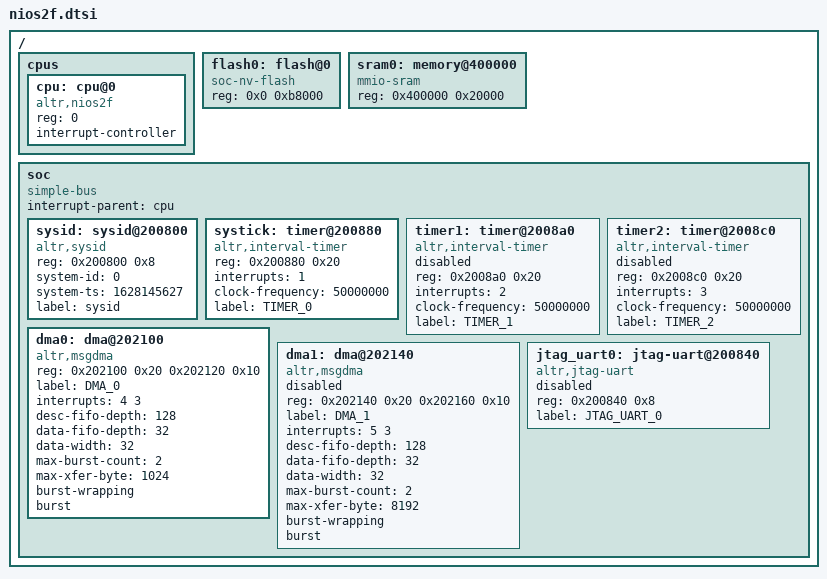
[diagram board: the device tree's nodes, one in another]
/*
 * Copyright (c) 2021 TiaC Systems
 * Copyright (c) 2018 Intel Corporation
 * SPDX-License-Identifier: Apache-2.0
 */

#include "skeleton.dtsi"

/ {
	cpus {
		#address-cells = <1>;
		#size-cells = <0>;

		cpu: cpu@0 {
			device_type = "cpu";
			compatible = "altr,nios2f";
			reg = <0>;
			interrupt-controller;
			#interrupt-cells = <1>;
		};
	};

	flash0: flash@0 {
		compatible = "soc-nv-flash";
		reg = <0x0 0xb8000>;
	};

	sram0: memory@400000 {
		compatible = "mmio-sram";
		reg = <0x400000 0x20000>;
	};

	soc {
		#address-cells = <1>;
		#size-cells = <1>;
		compatible = "simple-bus";
		interrupt-parent = <&cpu>;
		ranges;

		sysid: sysid@200800 {
			compatible = "altr,sysid";
			reg = <0x200800 0x8>;
			system-id = <0>;
			system-ts = <1628145627>;
			label = "sysid";
		};

		systick: timer@200880 {
			compatible = "altr,interval-timer";
			reg = <0x200880 0x20>;
			interrupts = <1>;
			clock-frequency = <50000000>;
			label = "TIMER_0";
		};

		timer1: timer@2008a0 {
			compatible = "altr,interval-timer";
			reg = <0x2008a0 0x20>;
			interrupts = <2>;
			clock-frequency = <50000000>;
			label = "TIMER_1";

			status = "disabled";
		};

		timer2: timer@2008c0 {
			compatible = "altr,interval-timer";
			reg = <0x2008c0 0x20>;
			interrupts = <3>;
			clock-frequency = <50000000>;
			label = "TIMER_2";

			status = "disabled";
		};

		dma0: dma@202100 {
			compatible = "altr,msgdma";
			reg = <0x202100 0x20
			       0x202120 0x10>;
			reg-names = "csr", "desc";
			label = "DMA_0";
			interrupts = <4 3>;
			#dma-cells = <0>;
			desc-fifo-depth = <128>;
			data-fifo-depth = <32>;
			data-width = <32>;
			max-burst-count = <2>;
			max-xfer-byte = <1024>;
			burst-wrapping;
			burst;
		};

		dma1: dma@202140 {
			compatible = "altr,msgdma";
			reg = <0x202140 0x20
			       0x202160 0x10>;
			reg-names = "csr", "desc";
			label = "DMA_1";
			interrupts = <5 3>;
			#dma-cells = <0>;
			desc-fifo-depth = <128>;
			data-fifo-depth = <32>;
			data-width = <32>;
			max-burst-count = <2>;
			max-xfer-byte = <8192>;
			burst-wrapping;
			burst;

			status = "disabled";
		};

		jtag_uart0: jtag-uart@200840 {
			compatible = "altr,jtag-uart";
			reg = <0x200840 0x8>;
			label = "JTAG_UART_0";

			status = "disabled";
		};
	};
};
